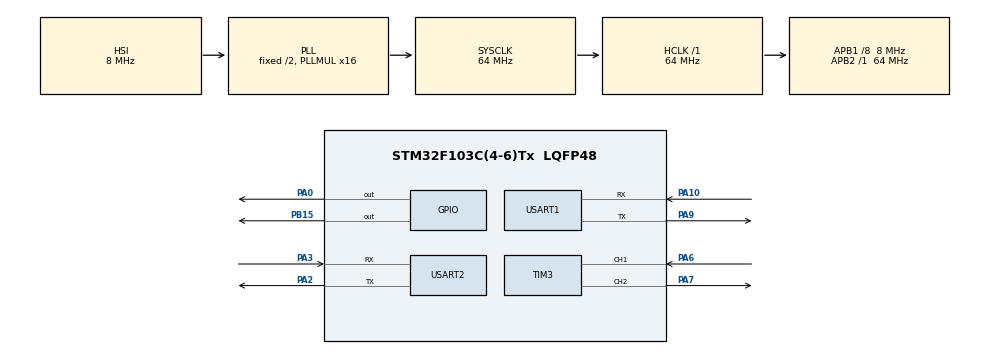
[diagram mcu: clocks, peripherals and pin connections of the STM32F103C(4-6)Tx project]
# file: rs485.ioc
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Mcu.Family=STM32F1
Mcu.Name=STM32F103C(4-6)Tx
Mcu.Package=LQFP48
NVIC.PriorityGroup=NVIC_PRIORITYGROUP_4
NVIC.TIM2_IRQn=true\:0\:0\:false\:false\:true\:true\:true\:true
NVIC.TIM3_IRQn=true\:0\:0\:false\:false\:true\:true\:true\:true
NVIC.USART1_IRQn=true\:0\:0\:false\:false\:true\:true\:true\:true
NVIC.USART2_IRQn=true\:0\:0\:false\:false\:true\:true\:true\:true
PA0-WKUP.GPIO_PuPd=GPIO_PULLDOWN
PA0-WKUP.Signal=GPIO_Output
PA10.Mode=Asynchronous
PA10.Signal=USART1_RX
PA2.Mode=Asynchronous
PA2.Signal=USART2_TX
PA3.Mode=Asynchronous
PA3.Signal=USART2_RX
PA6.Signal=S_TIM3_CH1
PA7.GPIO_Speed=GPIO_SPEED_FREQ_HIGH
PA7.Signal=S_TIM3_CH2
PA9.Mode=Asynchronous
PA9.Signal=USART1_TX
PB15.GPIO_PuPd=GPIO_PULLDOWN
PB15.Signal=GPIO_Output
ProjectManager.HeapSize=0x200
ProjectManager.StackSize=0x400
ProjectManager.TargetToolchain=STM32CubeIDE
RCC.AHBFreq_Value=64000000
RCC.APB1CLKDivider=RCC_HCLK_DIV8
RCC.APB1Freq_Value=8000000
RCC.APB1TimFreq_Value=16000000
RCC.APB2Freq_Value=64000000
RCC.APB2TimFreq_Value=64000000
RCC.HCLKFreq_Value=64000000
RCC.PLLMUL=RCC_PLL_MUL16
RCC.SYSCLKFreq_VALUE=64000000
RCC.SYSCLKSource=RCC_SYSCLKSOURCE_PLLCLK
RCC.USBFreq_Value=64000000
SH.S_TIM3_CH1.0=TIM3_CH1,Input_Capture1_from_TI1
SH.S_TIM3_CH2.0=TIM3_CH2,PWM Generation2 CH2
TIM2.Period=12288
TIM3.Channel-Input_Capture1_from_TI1=TIM_CHANNEL_1
TIM3.Channel-PWM\ Generation2\ CH2=TIM_CHANNEL_2
USART1.VirtualMode=VM_ASYNC
USART2.VirtualMode=VM_ASYNC
VP_TIM2_VS_ClockSourceITR.Mode=TriggerSource_ITR0
VP_TIM2_VS_ControllerModeClock.Mode=Clock Mode
VP_TIM3_VS_ClockSourceINT.Mode=Internal
board=custom

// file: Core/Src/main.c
/* USER CODE BEGIN Header */
/**
  ******************************************************************************
  * @file           : main.c
  * @brief          : Main program body
  ******************************************************************************
  * @attention
  *
  * Copyright (c) 2023 STMicroelectronics.
  * All rights reserved.
  *
  * This software is licensed under terms that can be found in the LICENSE file
  * in the root directory of this software component.
  * If no LICENSE file comes with this software, it is provided AS-IS.
  *
  ******************************************************************************
  */
/* USER CODE END Header */
#include "main.h"

TIM_HandleTypeDef htim2;
TIM_HandleTypeDef htim3;

UART_HandleTypeDef huart1;
UART_HandleTypeDef huart2;

void SystemClock_Config(void);
static void MX_GPIO_Init(void);
static void MX_TIM2_Init(void);
static void MX_USART1_UART_Init(void);
static void MX_USART2_UART_Init(void);
static void MX_TIM3_Init(void);

int main(void)
{
  /* USER CODE BEGIN 1 */
	uint8_t str[]= "USART Transmit\r\n";
  /* USER CODE END 1 */

  /* MCU Configuration--------------------------------------------------------*/

  /* Reset of all peripherals, Initializes the Flash interface and the Systick. */
  HAL_Init();

  /* Configure the system clock */
  SystemClock_Config();

  /* Initialize all configured peripherals */
  MX_GPIO_Init();
  MX_TIM2_Init();
  MX_USART1_UART_Init();
  MX_USART2_UART_Init();
  MX_TIM3_Init();
  /* USER CODE BEGIN 2 */
  uint8_t str1[]= "read1\r\n";
  HAL_UART_Transmit(&huart1,str1,7,0xFFFF);

  HAL_TIM_Base_Start(&htim3);
  HAL_TIM_Base_Start_IT(&htim3);
  HAL_TIM_PWM_Start(&htim3, TIM_CHANNEL_2);
  TIM3->CCR2=300000;

  /* USER CODE END 2 */

  /* Infinite loop */
  /* USER CODE BEGIN WHILE */
  while (1)
  {
	  HAL_GPIO_WritePin(GPIOA, GPIO_PIN_0, GPIO_PIN_SET);
	  HAL_UART_Transmit(&huart2,str,16,0xFFFF);
	  HAL_GPIO_WritePin(GPIOA, GPIO_PIN_0, GPIO_PIN_RESET);
	  HAL_Delay(1000);
    /* USER CODE END WHILE */

  }
}

void SystemClock_Config(void)
{
  RCC_OscInitTypeDef RCC_OscInitStruct = {0};
  RCC_ClkInitTypeDef RCC_ClkInitStruct = {0};

  /** Initializes the RCC Oscillators according to the specified parameters
  * in the RCC_OscInitTypeDef structure.
  */
  RCC_OscInitStruct.OscillatorType = RCC_OSCILLATORTYPE_HSI;
  RCC_OscInitStruct.HSIState = RCC_HSI_ON;
  RCC_OscInitStruct.HSICalibrationValue = RCC_HSICALIBRATION_DEFAULT;
  RCC_OscInitStruct.PLL.PLLState = RCC_PLL_ON;
  RCC_OscInitStruct.PLL.PLLSource = RCC_PLLSOURCE_HSI_DIV2;
  RCC_OscInitStruct.PLL.PLLMUL = RCC_PLL_MUL16;
  if (HAL_RCC_OscConfig(&RCC_OscInitStruct) != HAL_OK)
  {
    Error_Handler();
  }

  /** Initializes the CPU, AHB and APB buses clocks
  */
  RCC_ClkInitStruct.ClockType = RCC_CLOCKTYPE_HCLK|RCC_CLOCKTYPE_SYSCLK
                              |RCC_CLOCKTYPE_PCLK1|RCC_CLOCKTYPE_PCLK2;
  RCC_ClkInitStruct.SYSCLKSource = RCC_SYSCLKSOURCE_PLLCLK;
  RCC_ClkInitStruct.AHBCLKDivider = RCC_SYSCLK_DIV1;
  RCC_ClkInitStruct.APB1CLKDivider = RCC_HCLK_DIV8;
  RCC_ClkInitStruct.APB2CLKDivider = RCC_HCLK_DIV1;

  if (HAL_RCC_ClockConfig(&RCC_ClkInitStruct, FLASH_LATENCY_2) != HAL_OK)
  {
    Error_Handler();
  }
}

static void MX_TIM2_Init(void)
{

  TIM_SlaveConfigTypeDef sSlaveConfig = {0};
  TIM_MasterConfigTypeDef sMasterConfig = {0};

  htim2.Instance = TIM2;
  htim2.Init.Prescaler = 0;
  htim2.Init.CounterMode = TIM_COUNTERMODE_UP;
  htim2.Init.Period = 12288;
  htim2.Init.ClockDivision = TIM_CLOCKDIVISION_DIV1;
  htim2.Init.AutoReloadPreload = TIM_AUTORELOAD_PRELOAD_DISABLE;
  if (HAL_TIM_Base_Init(&htim2) != HAL_OK)
  {
    Error_Handler();
  }
  sSlaveConfig.SlaveMode = TIM_SLAVEMODE_EXTERNAL1;
  sSlaveConfig.InputTrigger = TIM_TS_ITR0;
  if (HAL_TIM_SlaveConfigSynchro(&htim2, &sSlaveConfig) != HAL_OK)
  {
    Error_Handler();
  }
  sMasterConfig.MasterOutputTrigger = TIM_TRGO_RESET;
  sMasterConfig.MasterSlaveMode = TIM_MASTERSLAVEMODE_DISABLE;
  if (HAL_TIMEx_MasterConfigSynchronization(&htim2, &sMasterConfig) != HAL_OK)
  {
    Error_Handler();
  }

}

static void MX_TIM3_Init(void)
{

  TIM_ClockConfigTypeDef sClockSourceConfig = {0};
  TIM_MasterConfigTypeDef sMasterConfig = {0};
  TIM_IC_InitTypeDef sConfigIC = {0};
  TIM_OC_InitTypeDef sConfigOC = {0};

  htim3.Instance = TIM3;
  htim3.Init.Prescaler = 0;
  htim3.Init.CounterMode = TIM_COUNTERMODE_UP;
  htim3.Init.Period = 65535;
  htim3.Init.ClockDivision = TIM_CLOCKDIVISION_DIV1;
  htim3.Init.AutoReloadPreload = TIM_AUTORELOAD_PRELOAD_DISABLE;
  if (HAL_TIM_Base_Init(&htim3) != HAL_OK)
  {
    Error_Handler();
  }
  sClockSourceConfig.ClockSource = TIM_CLOCKSOURCE_INTERNAL;
  if (HAL_TIM_ConfigClockSource(&htim3, &sClockSourceConfig) != HAL_OK)
  {
    Error_Handler();
  }
  if (HAL_TIM_IC_Init(&htim3) != HAL_OK)
  {
    Error_Handler();
  }
  if (HAL_TIM_PWM_Init(&htim3) != HAL_OK)
  {
    Error_Handler();
  }
  sMasterConfig.MasterOutputTrigger = TIM_TRGO_RESET;
  sMasterConfig.MasterSlaveMode = TIM_MASTERSLAVEMODE_DISABLE;
  if (HAL_TIMEx_MasterConfigSynchronization(&htim3, &sMasterConfig) != HAL_OK)
  {
    Error_Handler();
  }
  sConfigIC.ICPolarity = TIM_INPUTCHANNELPOLARITY_RISING;
  sConfigIC.ICSelection = TIM_ICSELECTION_DIRECTTI;
  sConfigIC.ICPrescaler = TIM_ICPSC_DIV1;
  sConfigIC.ICFilter = 0;
  if (HAL_TIM_IC_ConfigChannel(&htim3, &sConfigIC, TIM_CHANNEL_1) != HAL_OK)
  {
    Error_Handler();
  }
  sConfigOC.OCMode = TIM_OCMODE_PWM1;
  sConfigOC.Pulse = 0;
  sConfigOC.OCPolarity = TIM_OCPOLARITY_HIGH;
  sConfigOC.OCFastMode = TIM_OCFAST_DISABLE;
  if (HAL_TIM_PWM_ConfigChannel(&htim3, &sConfigOC, TIM_CHANNEL_2) != HAL_OK)
  {
    Error_Handler();
  }
  HAL_TIM_MspPostInit(&htim3);

}

static void MX_USART1_UART_Init(void)
{

  huart1.Instance = USART1;
  huart1.Init.BaudRate = 115200;
  huart1.Init.WordLength = UART_WORDLENGTH_8B;
  huart1.Init.StopBits = UART_STOPBITS_1;
  huart1.Init.Parity = UART_PARITY_NONE;
  huart1.Init.Mode = UART_MODE_TX_RX;
  huart1.Init.HwFlowCtl = UART_HWCONTROL_NONE;
  huart1.Init.OverSampling = UART_OVERSAMPLING_16;
  if (HAL_UART_Init(&huart1) != HAL_OK)
  {
    Error_Handler();
  }

}

static void MX_USART2_UART_Init(void)
{

  huart2.Instance = USART2;
  huart2.Init.BaudRate = 115200;
  huart2.Init.WordLength = UART_WORDLENGTH_8B;
  huart2.Init.StopBits = UART_STOPBITS_1;
  huart2.Init.Parity = UART_PARITY_NONE;
  huart2.Init.Mode = UART_MODE_TX_RX;
  huart2.Init.HwFlowCtl = UART_HWCONTROL_NONE;
  huart2.Init.OverSampling = UART_OVERSAMPLING_16;
  if (HAL_UART_Init(&huart2) != HAL_OK)
  {
    Error_Handler();
  }

}

static void MX_GPIO_Init(void)
{
  GPIO_InitTypeDef GPIO_InitStruct = {0};

  /* GPIO Ports Clock Enable */
  __HAL_RCC_GPIOA_CLK_ENABLE();
  __HAL_RCC_GPIOB_CLK_ENABLE();

  /*Configure GPIO pin Output Level */
  HAL_GPIO_WritePin(GPIOA, GPIO_PIN_0, GPIO_PIN_RESET);

  /*Configure GPIO pin Output Level */
  HAL_GPIO_WritePin(GPIOB, GPIO_PIN_15, GPIO_PIN_RESET);

  /*Configure GPIO pin : PA0 */
  GPIO_InitStruct.Pin = GPIO_PIN_0;
  GPIO_InitStruct.Mode = GPIO_MODE_OUTPUT_PP;
  GPIO_InitStruct.Pull = GPIO_PULLDOWN;
  GPIO_InitStruct.Speed = GPIO_SPEED_FREQ_LOW;
  HAL_GPIO_Init(GPIOA, &GPIO_InitStruct);

  /*Configure GPIO pin : PB15 */
  GPIO_InitStruct.Pin = GPIO_PIN_15;
  GPIO_InitStruct.Mode = GPIO_MODE_OUTPUT_PP;
  GPIO_InitStruct.Pull = GPIO_PULLDOWN;
  GPIO_InitStruct.Speed = GPIO_SPEED_FREQ_LOW;
  HAL_GPIO_Init(GPIOB, &GPIO_InitStruct);

}

void Error_Handler(void)
{
  __disable_irq();
  while (1)
  {
  }
}
